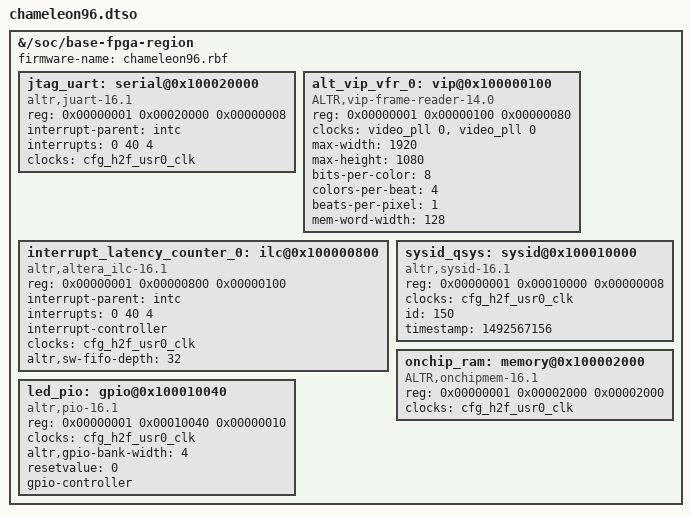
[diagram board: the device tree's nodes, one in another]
/*
 * This devicetree is generated by sopc2dts version rel_14.0_RC3-38-g6cfd69a on Thu May 04 00:51:20 EDT 2017
 * Sopc2dts is written by Walter Goossens <waltergoossens@home.nl>
 * in cooperation with the nios2 community <nios2-dev@lists.rocketboards.org>
 */
/dts-v1/ /plugin/;
/include/ "chameleon96.dtsi"

/ {

	fragment@0 {
		target-path = "/soc/base-fpga-region";

		__overlay__ {
			firmware-name = "chameleon96.rbf";
			#address-cells = <2>;
			#size-cells = <1>;
			ranges = <0x00000000 0x00000000 0xc0000000 0x20000000>,
				<0x00000001 0x00000000 0xff200000 0x00200000>;

			jtag_uart: serial@0x100020000 {
				compatible = "altr,juart-16.1", "altr,juart-1.0";
				reg = <0x00000001 0x00020000 0x00000008>;
				interrupt-parent = <&intc>;
				interrupts = <0 40 4>;
				clocks = <&cfg_h2f_usr0_clk>;
			}; //end serial@0x100020000 (jtag_uart)

			alt_vip_vfr_0: vip@0x100000100 {
				compatible = "ALTR,vip-frame-reader-14.0", "ALTR,vip-frame-reader-9.1";
				reg = <0x00000001 0x00000100 0x00000080>;
				clocks = <&video_pll 0 &video_pll 0>;
				clock-names = "clock_reset", "clock_master";
				max-width = <1920>;	/* MAX_IMAGE_WIDTH type NUMBER */
				max-height = <1080>;	/* MAX_IMAGE_HEIGHT type NUMBER */
				bits-per-color = <8>;	/* BITS_PER_PIXEL_PER_COLOR_PLANE type NUMBER */
				colors-per-beat = <4>;	/* NUMBER_OF_CHANNELS_IN_PARALLEL type NUMBER */
				beats-per-pixel = <1>;	/* NUMBER_OF_CHANNELS_IN_SEQUENCE type NUMBER */
				mem-word-width = <128>;	/* MEM_PORT_WIDTH type NUMBER */
			}; //end vip@0x100000100 (alt_vip_vfr_0)

			interrupt_latency_counter_0: ilc@0x100000800 {
				compatible = "altr,altera_ilc-16.1", "altr,ilc-1.0";
				reg = <0x00000001 0x00000800 0x00000100>;
				interrupt-parent = <&intc>;
				interrupts = <0 40 4>;
				interrupt-controller;
				#interrupt-cells = <1>;
				clocks = <&cfg_h2f_usr0_clk>;
				altr,sw-fifo-depth = <32>;	/* embeddedsw.dts.params.altr,sw-fifo-depth type NUMBER */
			}; //end ilc@0x100000800 (interrupt_latency_counter_0)

			sysid_qsys: sysid@0x100010000 {
				compatible = "altr,sysid-16.1", "altr,sysid-1.0";
				reg = <0x00000001 0x00010000 0x00000008>;
				clocks = <&cfg_h2f_usr0_clk>;
				id = <150>;	/* embeddedsw.dts.params.id type NUMBER */
				timestamp = <1492567156>;	/* embeddedsw.dts.params.timestamp type NUMBER */
			}; //end sysid@0x100010000 (sysid_qsys)

			onchip_ram: memory@0x100002000 {
				device_type = "memory";
				compatible = "ALTR,onchipmem-16.1";
				reg = <0x00000001 0x00002000 0x00002000>;
				clocks = <&cfg_h2f_usr0_clk>;
			}; //end memory@0x100002000 (onchip_ram)

			led_pio: gpio@0x100010040 {
				compatible = "altr,pio-16.1", "altr,pio-1.0";
				reg = <0x00000001 0x00010040 0x00000010>;
				clocks = <&cfg_h2f_usr0_clk>;
				altr,gpio-bank-width = <4>;	/* embeddedsw.dts.params.altr,gpio-bank-width type NUMBER */
				resetvalue = <0>;	/* embeddedsw.dts.params.resetvalue type NUMBER */
				#gpio-cells = <2>;
				gpio-controller;
			}; //end gpio@0x100010040 (led_pio)
		}; //end __overlay__
	}; //end fragment@0
}; //end /
